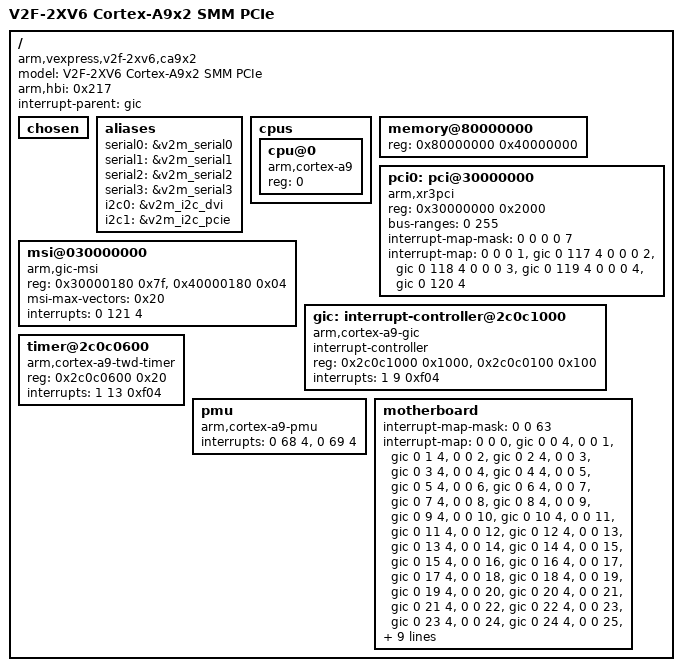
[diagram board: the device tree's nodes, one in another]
/*
 * ARM Ltd. Versatile Express
 *
 * LogicTile Express 13MG
 * V2F-2XV6
 *
 * Cortex-A9 (2 cores) Soft Macrocell Model with PLDA PCIe RC 
 *
 * HBI-0217A/B
 */

/dts-v1/;

/ {
	model = "V2F-2XV6 Cortex-A9x2 SMM PCIe";
	arm,hbi = <0x217>;
	compatible = "arm,vexpress,v2f-2xv6,ca9x2", "arm,vexpress,v2f-2xv6", "arm,vexpress";
	interrupt-parent = <&gic>;
	#address-cells = <1>;
	#size-cells = <1>;

	chosen { };

	aliases {
		serial0 = &v2m_serial0;
		serial1 = &v2m_serial1;
		serial2 = &v2m_serial2;
		serial3 = &v2m_serial3;
		i2c0 = &v2m_i2c_dvi;
		i2c1 = &v2m_i2c_pcie;
	};

	cpus {
		#address-cells = <1>;
		#size-cells = <0>;

		cpu@0 {
			device_type = "cpu";
			compatible = "arm,cortex-a9";
			reg = <0>;
		};
/*		cpu@1 {
			device_type = "cpu";
			compatible = "arm,cortex-a9";
			reg = <1>;
		};*/
	};

	memory@80000000 {
		device_type = "memory";
		reg = <0x80000000 0x40000000>;
	};

	pci0: pci@30000000 {
		compatible = "arm,xr3pci";
		device_type = "pci";
		reg = <0x30000000 0x2000>; //TODO 1000->2000 was a hack to make sure config space is mapped in
		bus-ranges = <0 255>;

		#address-cells = <3>;
		#size-cells = <2>;
			/* I/O is 0x2f000000 - 0x2fffffff */
			/* divided memory into prefetchable / non-prefetchable */
		ranges = <0x42000000 0 0x50000000 0x50000000 0 0x08000000 /* 32bit 256MB Prefetchable 1:1 */
		   	  0x02000000 0 0x40000000 0x40000000 0 0x8000000>; /* 32bit 256MB Non prefetchable 1:1 */

		#interrupt-cells = <1>;
		interrupt-map-mask = <0 0 0 0 7>;
		interrupt-map = <0 0 0 1 &gic 0 117 4
				 0 0 0 2 &gic 0 118 4
				 0 0 0 3 &gic 0 119 4
				 0 0 0 4 &gic 0 120 4>;
	};

	msi@030000000 {
		compatible = "arm,gic-msi";
		reg = <0x30000180 0x7f>,
		      <0x40000180 0x04>;  /* Interrupt and Event Registers of pci0 */
		msi-max-vectors = <0x20>;
                interrupts = <0 121 4>;
	};

	gic: interrupt-controller@2c0c1000 {
		compatible = "arm,cortex-a9-gic";
		#interrupt-cells = <3>;
		#address-cells = <0>;
		interrupt-controller;
		reg = <0x2c0c1000 0x1000>,
		      <0x2c0c0100 0x100>;
		interrupts = <1 9 0xf04>;
	};

        timer@2c0c0600 {
                compatible = "arm,cortex-a9-twd-timer";
                reg = <0x2c0c0600 0x20>;
                interrupts = <1 13 0xf04>;
        };

	pmu {
		compatible = "arm,cortex-a9-pmu";
		interrupts = <0 68 4>,
			     <0 69 4>;
	};

	motherboard {
		ranges = <0 0 0x08000000 0x04000000>,
			 <1 0 0x14000000 0x04000000>,
			 <2 0 0x18000000 0x04000000>,
			 <3 0 0x1c000000 0x04000000>,
			 <4 0 0x0c000000 0x04000000>,
			 <5 0 0x10000000 0x04000000>;

		interrupt-map-mask = <0 0 63>;
		interrupt-map = <0 0  0 &gic 0  0 4>,
				<0 0  1 &gic 0  1 4>,
				<0 0  2 &gic 0  2 4>,
				<0 0  3 &gic 0  3 4>,
				<0 0  4 &gic 0  4 4>,
				<0 0  5 &gic 0  5 4>,
				<0 0  6 &gic 0  6 4>,
				<0 0  7 &gic 0  7 4>,
				<0 0  8 &gic 0  8 4>,
				<0 0  9 &gic 0  9 4>,
				<0 0 10 &gic 0 10 4>,
				<0 0 11 &gic 0 11 4>,
				<0 0 12 &gic 0 12 4>,
				<0 0 13 &gic 0 13 4>,
				<0 0 14 &gic 0 14 4>,
				<0 0 15 &gic 0 15 4>,
				<0 0 16 &gic 0 16 4>,
				<0 0 17 &gic 0 17 4>,
				<0 0 18 &gic 0 18 4>,
				<0 0 19 &gic 0 19 4>,
				<0 0 20 &gic 0 20 4>,
				<0 0 21 &gic 0 21 4>,
				<0 0 22 &gic 0 22 4>,
				<0 0 23 &gic 0 23 4>,
				<0 0 24 &gic 0 24 4>,
				<0 0 25 &gic 0 25 4>,
				<0 0 26 &gic 0 26 4>,
				<0 0 27 &gic 0 27 4>,
				<0 0 28 &gic 0 28 4>,
				<0 0 29 &gic 0 29 4>,
				<0 0 30 &gic 0 30 4>,
				<0 0 31 &gic 0 31 4>,
				<0 0 32 &gic 0 32 4>,
				<0 0 33 &gic 0 33 4>,
				<0 0 34 &gic 0 34 4>,
				<0 0 35 &gic 0 35 4>,
				<0 0 36 &gic 0 36 4>,
				<0 0 37 &gic 0 37 4>,
				<0 0 38 &gic 0 38 4>,
				<0 0 39 &gic 0 39 4>,
				<0 0 40 &gic 0 40 4>,
				<0 0 41 &gic 0 41 4>,
				<0 0 42 &gic 0 42 4>;
	};
};

/include/ "vexpress-v2m-rs1.dtsi"
